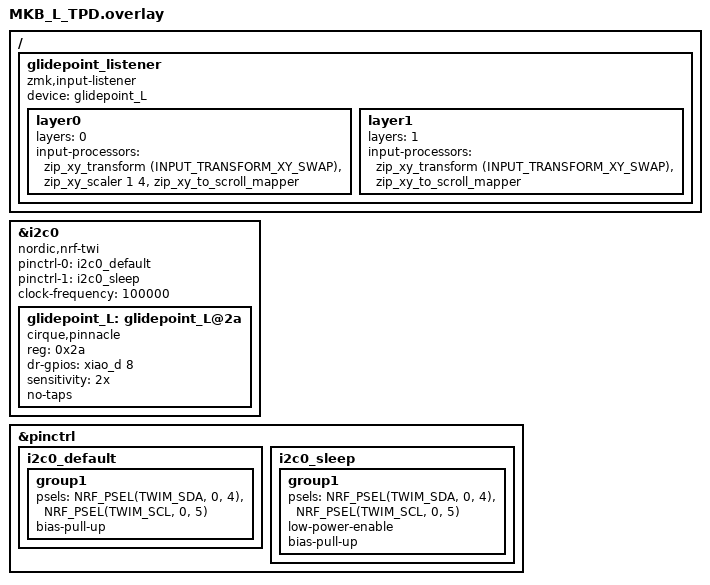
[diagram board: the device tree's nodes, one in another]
#include <dt-bindings/zmk/keys.h>
#include <dt-bindings/zmk/pointing.h>

&i2c0 {
    status = "okay";
    compatible = "nordic,nrf-twi";
    pinctrl-0 = <&i2c0_default>;
    pinctrl-1 = <&i2c0_sleep>;
    pinctrl-names = "default", "sleep";
    clock-frequency = <100000>; 
    
    glidepoint_L: glidepoint_L@2a {
            compatible = "cirque,pinnacle";
            reg = <0x2a>;
            status = "okay";
            dr-gpios = <&xiao_d 8 (GPIO_ACTIVE_HIGH)>;

            sensitivity = "2x";
            // sleep;
            no-taps;
        };
};

&pinctrl {    
    i2c0_default: i2c0_default {
        group1 {
            psels = <NRF_PSEL(TWIM_SDA, 0,  4)>,
                    <NRF_PSEL(TWIM_SCL, 0,  5)>;
            bias-pull-up;
        };
    };
      
    i2c0_sleep: i2c0_sleep {
        group1 {
            psels = <NRF_PSEL(TWIM_SDA, 0,  4)>,
                    <NRF_PSEL(TWIM_SCL, 0,  5)>;
            low-power-enable;
            bias-pull-up;
        };
    };
};

/ {
    glidepoint_listener: glidepoint_listener {
        compatible = "zmk,input-listener";
        status = "okay";
        device = <&glidepoint_L>;
        
        layer0 {
            layers = <0>;
            input-processors = <
                &zip_xy_transform (INPUT_TRANSFORM_XY_SWAP)
                &zip_xy_scaler 1 4
                &zip_xy_to_scroll_mapper
            >;
        };

        layer1 {
            layers = <1>;
            input-processors = <
                &zip_xy_transform (INPUT_TRANSFORM_XY_SWAP)
                &zip_xy_to_scroll_mapper
            >;
        };
    };
};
